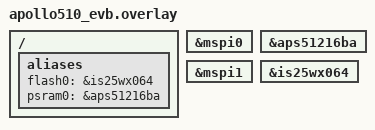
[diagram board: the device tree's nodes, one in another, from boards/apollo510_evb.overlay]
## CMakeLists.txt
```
# SPDX-License-Identifier: Apache-2.0

cmake_minimum_required(VERSION 3.28.0)
find_package(Zephyr REQUIRED HINTS $ENV{ZEPHYR_BASE})
project(mspi_timing_scan)

FILE(GLOB app_sources src/*.c)
target_sources(app PRIVATE ${app_sources})

if(CONFIG_MSPI)
  target_include_directories(app PRIVATE ${ZEPHYR_BASE}/include/zephyr/drivers)
  target_include_directories(app PRIVATE ${ZEPHYR_BASE}/drivers/mspi)
endif()
```

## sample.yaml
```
sample:
  name: MSPI Flash Sample
tests:
  sample.drivers.mspi.timing_scan.flash:
    tags:
      - mspi
    harness: console
    harness_config:
      type: multi_line
      ordered: true
      regex:
        - "MSPI Timing Scan is successful."
    platform_allow:
      - apollo510_evb
    integration_platforms:
      - apollo510_evb
    depends_on: mspi
    extra_configs:
      - CONFIG_FLASH=y
      - CONFIG_FLASH_INIT_PRIORITY=50
      - CONFIG_FLASH_MSPI_XIP_READ=y
      - CONFIG_MSPI_AMBIQ_TIMING_SCAN_BUFFER_SIZE=8192
      - CONFIG_MSPI_AMBIQ_TIMING_SCAN_DATA_SIZE=131072

  sample.drivers.mspi.timing_scan.memc:
    tags:
      - mspi
    harness: console
    harness_config:
      type: multi_line
      ordered: true
      regex:
        - "MSPI Timing Scan is successful."
    platform_allow:
      - apollo510_evb
    integration_platforms:
      - apollo510_evb
    depends_on: mspi
    extra_configs:
      - CONFIG_MEMC=y
      - CONFIG_MEMC_INIT_PRIORITY=50
```

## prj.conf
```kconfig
CONFIG_STDOUT_CONSOLE=y
CONFIG_MSPI=y
```

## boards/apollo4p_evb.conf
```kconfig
# Copyright (c) 2025 Ambiq Micro Inc. <www.ambiq.com>
# SPDX-License-Identifier: Apache-2.0

CONFIG_MSPI_AMBIQ_TIMING_SCAN=y
CONFIG_LOG=y
CONFIG_LOG_MODE_IMMEDIATE=y
CONFIG_LOG_DEFAULT_LEVEL=3
CONFIG_MSPI_LOG_LEVEL_INF=y
CONFIG_MSPI_INIT_PRIORITY=40
CONFIG_MAIN_STACK_SIZE=8192
CONFIG_PM_DEVICE=y
CONFIG_PM_DEVICE_RUNTIME=y
CONFIG_PM_DEVICE_RUNTIME_DEFAULT_ENABLE=n
```

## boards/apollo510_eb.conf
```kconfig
# Copyright (c) 2025 Ambiq Micro Inc. <www.ambiq.com>
# SPDX-License-Identifier: Apache-2.0

CONFIG_MSPI_AMBIQ_TIMING_SCAN=y
CONFIG_LOG=y
CONFIG_LOG_MODE_IMMEDIATE=y
CONFIG_LOG_DEFAULT_LEVEL=3
CONFIG_MSPI_LOG_LEVEL_INF=y
CONFIG_MSPI_INIT_PRIORITY=40
CONFIG_MAIN_STACK_SIZE=8192
CONFIG_PM_DEVICE=y
CONFIG_PM_DEVICE_RUNTIME_DEFAULT_ENABLE=n
```

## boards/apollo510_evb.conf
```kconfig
# Copyright (c) 2025 Ambiq Micro Inc. <www.ambiq.com>
# SPDX-License-Identifier: Apache-2.0

CONFIG_MSPI_AMBIQ_TIMING_SCAN=y
CONFIG_LOG=y
CONFIG_LOG_MODE_IMMEDIATE=y
CONFIG_LOG_DEFAULT_LEVEL=3
CONFIG_MSPI_LOG_LEVEL_INF=y
CONFIG_MSPI_INIT_PRIORITY=40
CONFIG_MAIN_STACK_SIZE=8192
```

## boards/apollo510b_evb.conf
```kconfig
# Copyright (c) 2025 Ambiq Micro Inc. <www.ambiq.com>
# SPDX-License-Identifier: Apache-2.0

CONFIG_MSPI_AMBIQ_TIMING_SCAN=y
CONFIG_MSPI_AMBIQ_CONTROLLER=y
CONFIG_MSPI_TIMING=y
CONFIG_MEMC=y
CONFIG_MEMC_MSPI_APS51216BA=y
CONFIG_MEMC_INIT_PRIORITY=50
CONFIG_LOG=y
CONFIG_LOG_MODE_IMMEDIATE=y
CONFIG_LOG_DEFAULT_LEVEL=3
CONFIG_MSPI_LOG_LEVEL_INF=y
CONFIG_MSPI_INIT_PRIORITY=40
CONFIG_MAIN_STACK_SIZE=8192
CONFIG_PM_DEVICE_RUNTIME_DEFAULT_ENABLE=n
```

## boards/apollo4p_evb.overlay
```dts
/*
 * Copyright (c) 2025, Ambiq Micro Inc. <www.ambiq.com>
 *
 * SPDX-License-Identifier: Apache-2.0
 */

&mspi0 {
	/delete-property/ zephyr,pm-device-runtime-auto;
};

&aps256n {
	/delete-property/ zephyr,pm-device-runtime-auto;
};

&mspi1 {
	/delete-property/ zephyr,pm-device-runtime-auto;
};
```

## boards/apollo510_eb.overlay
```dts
/*
 * Copyright (c) 2025, Ambiq Micro Inc. <www.ambiq.com>
 *
 * SPDX-License-Identifier: Apache-2.0
 */

/ {
	aliases {
		flash0 = &is25wx064;
		psram0 = &psram0;
	};
};

&mspi0 {
	/delete-property/ zephyr,pm-device-runtime-auto;
};

&psram0 {
	/delete-property/ zephyr,pm-device-runtime-auto;
};

&mspi1 {
	/delete-property/ zephyr,pm-device-runtime-auto;
};
```

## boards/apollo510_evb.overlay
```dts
/*
 * Copyright (c) 2025, Ambiq Micro Inc. <www.ambiq.com>
 *
 * SPDX-License-Identifier: Apache-2.0
 */

/ {
	aliases {
		flash0 = &is25wx064;
		psram0 = &aps51216ba;
	};
};

&mspi0 {
	/delete-property/ zephyr,pm-device-runtime-auto;
	status = "okay";
};

&aps51216ba {
	/delete-property/ zephyr,pm-device-runtime-auto;
	status = "okay";
};

&mspi1 {
	/delete-property/ zephyr,pm-device-runtime-auto;
	status = "okay";
};

&is25wx064 {
	status = "okay";
};
```

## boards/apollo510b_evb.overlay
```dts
/*
 * Copyright (c) 2025, Ambiq Micro Inc. <www.ambiq.com>
 *
 * SPDX-License-Identifier: Apache-2.0
 */

/ {
	aliases {
		psram0 = &aps51216ba;
	};
};

&mspi0 {
	/delete-property/ zephyr,pm-device-runtime-auto;
	status = "okay";
};

&aps51216ba {
	/delete-property/ zephyr,pm-device-runtime-auto;
	status = "okay";
};
```

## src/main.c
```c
/*
 * Copyright (c) 2025 Ambiq Micro Inc. <www.ambiq.com>
 *
 * SPDX-License-Identifier: Apache-2.0
 */

#include <zephyr/kernel.h>
#include <zephyr/drivers/flash.h>
#include <zephyr/drivers/mspi.h>
#include <zephyr/device.h>
#include <zephyr/devicetree.h>
#include <stdio.h>
#include <string.h>

#include "mspi_ambiq.h"

#if CONFIG_FLASH_MSPI
#define TARGET_DEVICE DT_ALIAS(flash0)
#elif CONFIG_MEMC_MSPI
#define TARGET_DEVICE DT_ALIAS(psram0)
#else
#error "Unsupported device type!!"
#endif

#define MSPI_AMBIQ_TIMING_CONFIG_DT(n)                                                       \
	{                                                                                    \
		.ui8WriteLatency    = DT_PROP_BY_IDX(n, ambiq_timing_config, 0),             \
		.ui8TurnAround      = DT_PROP_BY_IDX(n, ambiq_timing_config, 1),             \
		.bTxNeg             = DT_PROP_BY_IDX(n, ambiq_timing_config, 2),             \
		.bRxNeg             = DT_PROP_BY_IDX(n, ambiq_timing_config, 3),             \
		.bRxCap             = DT_PROP_BY_IDX(n, ambiq_timing_config, 4),             \
		.ui32TxDQSDelay     = DT_PROP_BY_IDX(n, ambiq_timing_config, 5),             \
		.ui32RxDQSDelay     = DT_PROP_BY_IDX(n, ambiq_timing_config, 6),             \
	}

#define MSPI_AMBIQ_TIMING_CONFIG_MASK_DT(n) DT_PROP(n, ambiq_timing_config_mask)

int main(void)
{
	const struct device *tar_bus = DEVICE_DT_GET(DT_BUS(TARGET_DEVICE));
	const struct device *tar_dev = DEVICE_DT_GET(TARGET_DEVICE);
	struct mspi_dev_id dev_id = MSPI_DEVICE_ID_DT(TARGET_DEVICE);
#if CONFIG_MEMC_MSPI
	struct mspi_memmap_cfg tar_memmap_cfg = MSPI_MEMMAP_CONFIG_DT(TARGET_DEVICE);
#endif
	struct mspi_ambiq_timing_cfg tar_timing_cfg = MSPI_AMBIQ_TIMING_CONFIG_DT(TARGET_DEVICE);
	uint32_t timing_cfg_mask = MSPI_AMBIQ_TIMING_CONFIG_MASK_DT(TARGET_DEVICE);
	struct mspi_ambiq_timing_scan scan;

	if (!device_is_ready(tar_dev)) {
		printf("%s: device not ready.\n", tar_dev->name);
		return 1;
	}

#if CONFIG_MEMC_MSPI
	if (!tar_memmap_cfg.enable) {
		printf("Need to enable XIP for timing scan.\n");
		return 1;
	}
#endif

	memset(&scan, 0, sizeof(struct mspi_ambiq_timing_scan));
	scan.range.txdqs_end  = 10;
	scan.range.rxdqs_end  = 31;
#if CONFIG_FLASH_MSPI
	scan.scan_type        = MSPI_AMBIQ_TIMING_SCAN_FLASH;
#elif CONFIG_MEMC_MSPI
	uint32_t base_addr    = DT_REG_ADDR_BY_IDX(DT_BUS(TARGET_DEVICE), 1);

	scan.scan_type        = MSPI_AMBIQ_TIMING_SCAN_MEMC;
	scan.device_addr      = base_addr +
				tar_memmap_cfg.address_offset +
				tar_memmap_cfg.size / 2;
#endif
	scan.min_window       = 6;
	printf("Starting MSPI Timing Scan.\n");
	if (mspi_ambiq_timing_scan(tar_dev, tar_bus, &dev_id, timing_cfg_mask,
				   (void *)&tar_timing_cfg, &scan)) {
		printf("Failed to timing scan\n");
		return 1;
	}
	printf("MSPI Timing Scan is successful.\n");
	printf("==========================\n");
	return 0;
}
```
